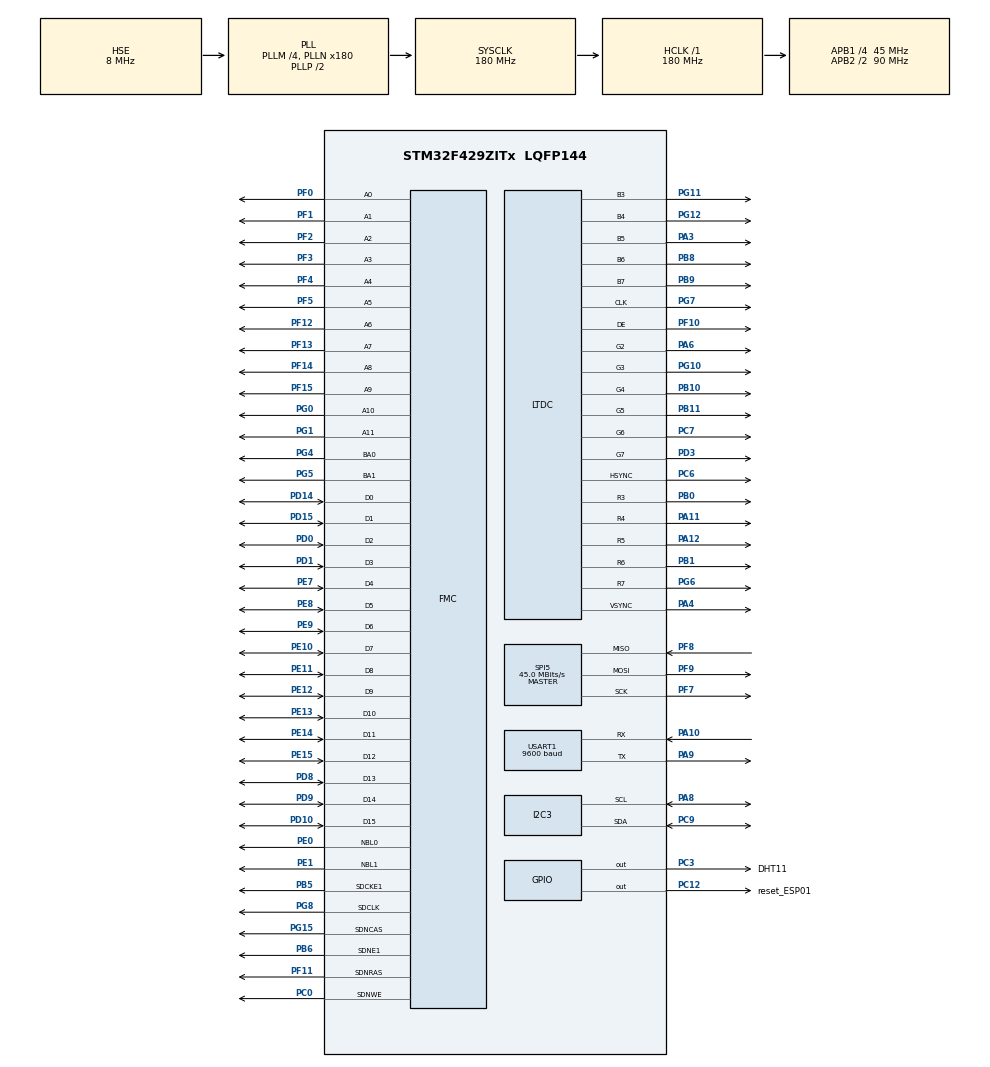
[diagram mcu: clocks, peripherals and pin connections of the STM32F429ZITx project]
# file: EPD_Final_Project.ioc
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DMA2D.ColorMode=DMA2D_OUTPUT_RGB565
LTDC.ActiveH=320
LTDC.ActiveW=240
LTDC.Alpha_L0=255
LTDC.BlendingFactor1_L0=LTDC_BLENDING_FACTOR1_PAxCA
LTDC.BlendingFactor2_L0=LTDC_BLENDING_FACTOR2_PAxCA
LTDC.HBP=20
LTDC.HFP=10
LTDC.HSync=10
LTDC.ImageHeight_L0=320
LTDC.ImageWidth_L0=240
LTDC.Layers=0
LTDC.PixelFormat_L0=LTDC_PIXEL_FORMAT_RGB565
LTDC.VFP=4
LTDC.VSync=2
LTDC.WindowX1_L0=240
LTDC.WindowY1_L0=320
Mcu.Family=STM32F4
Mcu.Name=STM32F429ZITx
Mcu.Package=LQFP144
NVIC.LTDC_IRQn=true\:1\:0\:true\:false\:true\:true\:true\:true
NVIC.PriorityGroup=NVIC_PRIORITYGROUP_4
PA10.Mode=Asynchronous
PA10.Signal=USART1_RX
PA11.Mode=RGB565
PA11.Signal=LTDC_R4
PA12.Mode=RGB565
PA12.Signal=LTDC_R5
PA13.Mode=Serial_Wire
PA13.Signal=SYS_JTMS-SWDIO
PA14.Mode=Serial_Wire
PA14.Signal=SYS_JTCK-SWCLK
PA3.Mode=RGB565
PA3.Signal=LTDC_B5
PA4.Mode=RGB565
PA4.Signal=LTDC_VSYNC
PA6.Mode=RGB565
PA6.Signal=LTDC_G2
PA8.Mode=I2C
PA8.Signal=I2C3_SCL
PA9.Mode=Asynchronous
PA9.Signal=USART1_TX
PB0.Mode=RGB565
PB0.Signal=LTDC_R3
PB1.Mode=RGB565
PB1.Signal=LTDC_R6
PB10.Mode=RGB565
PB10.Signal=LTDC_G4
PB11.Mode=RGB565
PB11.Signal=LTDC_G5
PB5.Mode=SdramChipSelect2_1
PB5.Signal=FMC_SDCKE1
PB6.Mode=SdramChipSelect2_1
PB6.Signal=FMC_SDNE1
PB8.Mode=RGB565
PB8.Signal=LTDC_B6
PB9.Mode=RGB565
PB9.Signal=LTDC_B7
PC0.Signal=FMC_SDNWE
PC12.GPIO_Label=reset_ESP01
PC12.GPIO_ModeDefaultOutputPP=GPIO_MODE_OUTPUT_PP
PC12.GPIO_PuPd=GPIO_PULLUP
PC12.GPIO_Speed=GPIO_SPEED_FREQ_VERY_HIGH
PC12.PinState=GPIO_PIN_SET
PC12.Signal=GPIO_Output
PC3.GPIO_Label=DHT11
PC3.Signal=GPIO_Output
PC6.Mode=RGB565
PC6.Signal=LTDC_HSYNC
PC7.Mode=RGB565
PC7.Signal=LTDC_G6
PC9.Mode=I2C
PC9.Signal=I2C3_SDA
PD0.Signal=FMC_D2_DA2
PD1.Signal=FMC_D3_DA3
PD10.Signal=FMC_D15_DA15
PD14.Signal=FMC_D0_DA0
PD15.Signal=FMC_D1_DA1
PD3.Mode=RGB565
PD3.Signal=LTDC_G7
PD8.Signal=FMC_D13_DA13
PD9.Signal=FMC_D14_DA14
PE0.Signal=FMC_NBL0
PE1.Signal=FMC_NBL1
PE10.Signal=FMC_D7_DA7
PE11.Signal=FMC_D8_DA8
PE12.Signal=FMC_D9_DA9
PE13.Signal=FMC_D10_DA10
PE14.Signal=FMC_D11_DA11
PE15.Signal=FMC_D12_DA12
PE7.Signal=FMC_D4_DA4
PE8.Signal=FMC_D5_DA5
PE9.Signal=FMC_D6_DA6
PF0.Signal=FMC_A0
PF1.Signal=FMC_A1
PF10.Mode=RGB565
PF10.Signal=LTDC_DE
PF11.Signal=FMC_SDNRAS
PF12.Signal=FMC_A6
PF13.Signal=FMC_A7
PF14.Signal=FMC_A8
PF15.Signal=FMC_A9
PF2.Signal=FMC_A2
PF3.Signal=FMC_A3
PF4.Signal=FMC_A4
PF5.Signal=FMC_A5
PF7.Mode=Full_Duplex_Master
PF7.Signal=SPI5_SCK
PF8.Mode=Full_Duplex_Master
PF8.Signal=SPI5_MISO
PF9.Mode=Full_Duplex_Master
PF9.Signal=SPI5_MOSI
PG0.Signal=FMC_A10
PG1.Signal=FMC_A11
PG10.Mode=RGB565
PG10.Signal=LTDC_G3
PG11.Mode=RGB565
PG11.Signal=LTDC_B3
PG12.Mode=RGB565
PG12.Signal=LTDC_B4
PG15.Signal=FMC_SDNCAS
PG4.Signal=FMC_A14_BA0
PG5.Signal=FMC_A15_BA1
PG6.Mode=RGB565
PG6.Signal=LTDC_R7
PG7.Mode=RGB565
PG7.Signal=LTDC_CLK
PG8.Signal=FMC_SDCLK
PH0/OSC_IN.Mode=HSE-External-Oscillator
PH0/OSC_IN.Signal=RCC_OSC_IN
PH1/OSC_OUT.Mode=HSE-External-Oscillator
PH1/OSC_OUT.Signal=RCC_OSC_OUT
ProjectManager.HeapSize=0x200
ProjectManager.StackSize=0x400
ProjectManager.TargetToolchain=STM32CubeIDE
RCC.48MHZClocksFreq_Value=90000000
RCC.AHBFreq_Value=180000000
RCC.APB1CLKDivider=RCC_HCLK_DIV4
RCC.APB1Freq_Value=45000000
RCC.APB1TimFreq_Value=90000000
RCC.APB2CLKDivider=RCC_HCLK_DIV2
RCC.APB2Freq_Value=90000000
RCC.APB2TimFreq_Value=180000000
RCC.CortexFreq_Value=180000000
RCC.EnbaleCSS=true
RCC.HCLKFreq_Value=180000000
RCC.HSE_VALUE=8000000
RCC.HSI_VALUE=16000000
RCC.LSE_VALUE=32768
RCC.PLLM=4
RCC.PLLN=180
RCC.PLLSAIN=50
RCC.PLLSAIR=4
RCC.PLLSourceVirtual=RCC_PLLSOURCE_HSE
RCC.RCC_RTC_Clock_Source=RCC_RTCCLKSOURCE_LSI
RCC.RCC_RTC_Clock_SourceVirtual=RCC_RTCCLKSOURCE_LSE
RCC.RCC_RTC_Clock_Source_FROM_HSE=RCC_RTCCLKSOURCE_HSE_DIV8
RCC.SYSCLKFreq_VALUE=180000000
RCC.SYSCLKSource=RCC_SYSCLKSOURCE_PLLCLK
RCC.VCOOutputFreq_Value=360000000
RTC.Date=27
RTC.Format=RTC_FORMAT_BIN
RTC.Hours=9
RTC.Minutes=10
RTC.Month=RTC_MONTH_MAY
RTC.WeekDay=RTC_WEEKDAY_SATURDAY
RTC.Year=23
SH.FMC_A0.0=FMC_A0,12b-sda1
SH.FMC_A1.0=FMC_A1,12b-sda1
SH.FMC_A10.0=FMC_A10,12b-sda1
SH.FMC_A11.0=FMC_A11,12b-sda1
SH.FMC_A14_BA0.0=FMC_BA0,FourSdramBanks1
SH.FMC_A15_BA1.0=FMC_BA1,FourSdramBanks1
SH.FMC_A2.0=FMC_A2,12b-sda1
SH.FMC_A3.0=FMC_A3,12b-sda1
SH.FMC_A4.0=FMC_A4,12b-sda1
SH.FMC_A5.0=FMC_A5,12b-sda1
SH.FMC_A6.0=FMC_A6,12b-sda1
SH.FMC_A7.0=FMC_A7,12b-sda1
SH.FMC_A8.0=FMC_A8,12b-sda1
SH.FMC_A9.0=FMC_A9,12b-sda1
SH.FMC_D0_DA0.0=FMC_D0,sd-16b-d1
SH.FMC_D10_DA10.0=FMC_D10,sd-16b-d1
SH.FMC_D11_DA11.0=FMC_D11,sd-16b-d1
SH.FMC_D12_DA12.0=FMC_D12,sd-16b-d1
SH.FMC_D13_DA13.0=FMC_D13,sd-16b-d1
SH.FMC_D14_DA14.0=FMC_D14,sd-16b-d1
SH.FMC_D15_DA15.0=FMC_D15,sd-16b-d1
SH.FMC_D1_DA1.0=FMC_D1,sd-16b-d1
SH.FMC_D2_DA2.0=FMC_D2,sd-16b-d1
SH.FMC_D3_DA3.0=FMC_D3,sd-16b-d1
SH.FMC_D4_DA4.0=FMC_D4,sd-16b-d1
SH.FMC_D5_DA5.0=FMC_D5,sd-16b-d1
SH.FMC_D6_DA6.0=FMC_D6,sd-16b-d1
SH.FMC_D7_DA7.0=FMC_D7,sd-16b-d1
SH.FMC_D8_DA8.0=FMC_D8,sd-16b-d1
SH.FMC_D9_DA9.0=FMC_D9,sd-16b-d1
SH.FMC_NBL0.0=FMC_NBL0,Sd2ByteEnable1
SH.FMC_NBL1.0=FMC_NBL1,Sd2ByteEnable1
SH.FMC_SDCLK.0=FMC_SDCLK,12b-sda1
SH.FMC_SDNCAS.0=FMC_SDNCAS,12b-sda1
SH.FMC_SDNRAS.0=FMC_SDNRAS,12b-sda1
SH.FMC_SDNWE.0=FMC_SDNWE,12b-sda1
SPI5.CalculateBaudRate=45.0 MBits/s
SPI5.Direction=SPI_DIRECTION_2LINES
SPI5.Mode=SPI_MODE_MASTER
SPI5.VirtualType=VM_MASTER
TIM6.Prescaler=90-1
USART1.BaudRate=9600
USART1.VirtualMode=VM_ASYNC
VP_DMA2D_VS_DMA2D.Mode=DMA2D_Activate
VP_RTC_VS_RTC_Activate.Mode=RTC_Enabled
VP_RTC_VS_RTC_Calendar.Mode=RTC_Calendar
VP_TIM6_VS_ClockSourceINT.Mode=Enable_Timer
board=custom

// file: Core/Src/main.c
/* USER CODE BEGIN Header */
/**
  ******************************************************************************
  * @file           : main.c
  * @brief          : Main program body
  ******************************************************************************
  * @attention
  *
  * Copyright (c) 2023 STMicroelectronics.
  * All rights reserved.
  *
  * This software is licensed under terms that can be found in the LICENSE file
  * in the root directory of this software component.
  * If no LICENSE file comes with this software, it is provided AS-IS.
  *
  ******************************************************************************
  */
/* USER CODE END Header */
#include "main.h"
#include "dma2d.h"
#include "i2c.h"
#include "ltdc.h"
#include "rtc.h"
#include "spi.h"
#include "tim.h"
#include "usart.h"
#include "gpio.h"
#include "fmc.h"

/* USER CODE BEGIN Includes */
#include <stdio.h>
#include <string.h>
#include "stm32f429i_discovery_lcd.h"
#include <stdio.h>
#include "./image/display_1.h"
#include "./image/display_2.h"

/* ESP8266 part(start) */
void ESP8266_Init();
void ESP8266_SendData(int16_t sensor1_data,int16_t sensor2_data);
int32_t checkBufferCharacters(uint8_t* buffer, const char* targetString);
/* ESP8266 part(end) */

/* USER CODE END Includes */

/* USER CODE BEGIN PD */

#define DHT22_PORT GPIOC
#define DHT22_PIN GPIO_PIN_3

/* USER CODE END PD */

/* USER CODE BEGIN PV */

uint8_t 	stimebuf[30]={0};
uint8_t 	sdatebuf[30]={0};
RTC_TimeTypeDef sTime={0};
RTC_DateTypeDef sDate={0};

/* ESP8266 part(start) */
uint8_t at_inst1[]="AT+CIPSTART=\"TCP\",\"184.106.153.149\",80\r\n";
char at_inst2[16];
uint8_t at_inst4[]="AT+CIPCLOSE\r\n";

#define BUFFER_SIZE 64
uint8_t rx_buffer_init[128];
uint8_t rx_buffer1[BUFFER_SIZE];
uint8_t rx_buffer2[BUFFER_SIZE];
uint8_t rx_buffer3[BUFFER_SIZE];
uint8_t rx_buffer4[BUFFER_SIZE];

int32_t init_receive_ok=0;
int32_t inst1_receive_ok=0;
int32_t inst2_receive_ok=0;
int32_t inst3_receive_ok=0;
int32_t inst4_receive_ok=0;

int32_t timeout=0;

/* ESP8266 part(end) */

/* DHT11 part(start) */
void delay (uint16_t time);
void Set_Pin_Output (GPIO_TypeDef *GPIOx, uint16_t GPIO_Pin);
void Set_Pin_Input (GPIO_TypeDef *GPIOx, uint16_t GPIO_Pin);
void DHT22_Start (void);
uint8_t DHT22_Check_Response (void);
uint8_t DHT22_Read (void);
uint8_t Rh_byte1, Rh_byte2, Temp_byte1, Temp_byte2;
uint16_t SUM, RH, TEMP;
int16_t Temperature = 0;
int16_t Humidity = 0;
uint8_t Presence = 0;
int32_t timeout_DHT=0;
/* DHT11 part(end) */

uint8_t humidityString[10] = {0};
uint8_t TemperatureString[10] = {0};

/* USER CODE END PV */

void SystemClock_Config(void);

int main(void)
{

  /* MCU Configuration--------------------------------------------------------*/

  /* Reset of all peripherals, Initializes the Flash interface and the Systick. */
     HAL_Init();

  /* Configure the system clock */
  SystemClock_Config();

  /* Initialize all configured peripherals */
  MX_GPIO_Init();
  MX_DMA2D_Init();
  MX_LTDC_Init();
  MX_FMC_Init();
  MX_I2C3_Init();
  MX_SPI5_Init();
  MX_TIM6_Init();
  MX_USART1_UART_Init();
  MX_RTC_Init();
  /* USER CODE BEGIN 2 */
  BSP_LCD_Init();

  BSP_LCD_LayerDefaultInit(LCD_BACKGROUND_LAYER, LCD_FRAME_BUFFER);
  BSP_LCD_LayerDefaultInit(LCD_FOREGROUND_LAYER, LCD_FRAME_BUFFER);
  BSP_LCD_SelectLayer(LCD_FOREGROUND_LAYER);
  BSP_LCD_DisplayOn();
  BSP_LCD_Clear(LCD_COLOR_GRAY);
  HAL_TIM_Base_Start(&htim6);

  /* USER CODE END 2 */

  /* Infinite loop */
  /* USER CODE BEGIN WHILE */
  while (1)
  {
	  HAL_RTC_GetTime(&hrtc, &sTime, RTC_FORMAT_BIN);
	  HAL_RTC_GetDate(&hrtc, &sDate, RTC_FORMAT_BIN);

	  sprintf ((char*)stimebuf,"%02u:%02u",sTime.Hours, sTime.Minutes);
	  BSP_LCD_DrawRect(0,0,240,18);
	  BSP_LCD_SetTextColor(LCD_COLOR_DARKGRAY);
	  BSP_LCD_FillRect(0,0,240,18);
	  BSP_LCD_SetFont(&Font16);
	  BSP_LCD_SetTextColor(LCD_COLOR_WHITE);
	  BSP_LCD_SetBackColor(LCD_COLOR_DARKGRAY);
	  BSP_LCD_DisplayStringAt(0, 0, stimebuf, RIGHT_MODE);

	  sprintf ((char*)sdatebuf,"%02u/%02u/%02u",sDate.Year, sDate.Month,sDate.Date);
	  BSP_LCD_SetFont(&Font16);
	  BSP_LCD_SetTextColor(LCD_COLOR_WHITE);
	  BSP_LCD_SetBackColor(LCD_COLOR_DARKGRAY);
	  BSP_LCD_DisplayStringAt(0, 0, sdatebuf, LEFT_MODE);
	  //
	  //
	  BSP_LCD_SetFont(&Font24);
	  BSP_LCD_SetTextColor(LCD_COLOR_WHITE);
	  BSP_LCD_SetBackColor(LCD_COLOR_DARKGRAY);
	  BSP_LCD_DisplayStringAtLine(2, (uint8_t*) "Temperature       ");
	  //
	  BSP_LCD_SetFont(&Font24);
	  BSP_LCD_SetTextColor(LCD_COLOR_WHITE);
	  BSP_LCD_SetBackColor(LCD_COLOR_DARKGRAY);
	  BSP_LCD_DisplayStringAtLine(5, (uint8_t*) "Humidity         ");
	  //
	  BSP_LCD_SetFont(&Font24);
	  BSP_LCD_SetTextColor(LCD_COLOR_WHITE);
	  BSP_LCD_SetBackColor(LCD_COLOR_DARKGRAY);
	  BSP_LCD_DisplayStringAtLine(8, (uint8_t*) "State             ");
	  //
	  BSP_LCD_DrawRect(95,233,20,20);
	  BSP_LCD_SetTextColor(LCD_COLOR_ORANGE);
	  BSP_LCD_FillRect(95,233,20,20);
	  BSP_LCD_SetFont(&Font20);
	  BSP_LCD_SetTextColor(LCD_COLOR_BLACK);
	  BSP_LCD_SetBackColor(LCD_COLOR_GRAY);
	  BSP_LCD_DisplayStringAt(0, 235, (uint8_t*)"Sensor", LEFT_MODE);
	  //
	  BSP_LCD_SetFont(&Font16);
	  BSP_LCD_SetTextColor(LCD_COLOR_BLACK);
	  BSP_LCD_SetBackColor(LCD_COLOR_GRAY);
	  BSP_LCD_DisplayStringAt(0, 270, (uint8_t*)"    :Done", LEFT_MODE);
	  BSP_LCD_DrawRect(27,267,15,15);
	  BSP_LCD_SetTextColor(LCD_COLOR_GREEN);
	  BSP_LCD_FillRect(27,267,15,15);
	  //
	  BSP_LCD_SetFont(&Font16);
	  BSP_LCD_SetTextColor(LCD_COLOR_BLACK);
	  BSP_LCD_SetBackColor(LCD_COLOR_GRAY);
	  BSP_LCD_DisplayStringAt(0, 270, (uint8_t*)":Working ", RIGHT_MODE);
	  BSP_LCD_DrawRect(115,267,15,15);
	  BSP_LCD_SetTextColor(LCD_COLOR_ORANGE);
	  BSP_LCD_FillRect(115,267,15,15);
	  //
	  BSP_LCD_SetFont(&Font16);
	  BSP_LCD_SetTextColor(LCD_COLOR_BLACK);
	  BSP_LCD_SetBackColor(LCD_COLOR_GRAY);
	  BSP_LCD_DisplayStringAt(0, 295, (uint8_t*)"   :Failed", CENTER_MODE);
	  BSP_LCD_DrawRect(75,292,15,15);
	  BSP_LCD_SetTextColor(LCD_COLOR_RED);
	  BSP_LCD_FillRect(75,292,15,15);
	  //
	  HAL_Delay(1500);
	  DHT22_Start();
	  Presence = DHT22_Check_Response();
	  if (Presence!=1)
	  {
		  HAL_Delay(3000);
		  timeout_DHT=0;
		  continue;
	  }
	  Rh_byte1 = DHT22_Read ();
	  Rh_byte2 = DHT22_Read ();
	  Temp_byte1 = DHT22_Read ();
	  Temp_byte2 = DHT22_Read ();
	  SUM = DHT22_Read();
	  if (SUM == (Rh_byte1+Rh_byte2+Temp_byte1+Temp_byte2))
	  {
	  Temperature = (Temp_byte1<<8|Temp_byte2)/10;
	  Humidity = (Rh_byte1<<8|Rh_byte2)/10;
	  //
	  BSP_LCD_DrawRect(95,233,20,20);
	  BSP_LCD_SetTextColor(LCD_COLOR_GREEN);
	  BSP_LCD_FillRect(95,233,20,20);
	  }
	  //Temperature++;
	  //Humidity++;
	  //
	  sprintf((char*)TemperatureString, "%d.c", Temperature);
	  BSP_LCD_SetFont(&Font24);
	  BSP_LCD_SetTextColor(LCD_COLOR_BLACK);
	  BSP_LCD_SetBackColor(LCD_COLOR_GRAY);
	  BSP_LCD_DisplayStringAt(0, 90, TemperatureString, CENTER_MODE);
	  //
	  sprintf((char*)humidityString, "%d%%", Humidity);
	  BSP_LCD_SetFont(&Font24);
	  BSP_LCD_SetTextColor(LCD_COLOR_BLACK);
	  BSP_LCD_SetBackColor(LCD_COLOR_GRAY);
	  BSP_LCD_DisplayStringAt(0,162,humidityString, CENTER_MODE);
	  HAL_Delay(1000);
	  //
	  BSP_LCD_SetFont(&Font20);
	  BSP_LCD_SetTextColor(LCD_COLOR_BLACK);
	  BSP_LCD_SetBackColor(LCD_COLOR_GRAY);
	  BSP_LCD_DisplayStringAt(0, 235, (uint8_t*)"Upload  ", RIGHT_MODE);
	  BSP_LCD_DrawRect(215,233,20,20);
	  BSP_LCD_SetTextColor(LCD_COLOR_ORANGE);
	  BSP_LCD_FillRect(215,233,20,20);
	  //
	  ESP8266_Init();
	  ESP8266_SendData(Temperature, Humidity);
	  Presence = 0;
	  HAL_Delay(1500);
	  init_receive_ok=0;

    /* USER CODE END WHILE */

  }
}

void SystemClock_Config(void)
{
  RCC_OscInitTypeDef RCC_OscInitStruct = {0};
  RCC_ClkInitTypeDef RCC_ClkInitStruct = {0};

  /** Configure the main internal regulator output voltage
  */
  __HAL_RCC_PWR_CLK_ENABLE();
  __HAL_PWR_VOLTAGESCALING_CONFIG(PWR_REGULATOR_VOLTAGE_SCALE1);

  /** Initializes the RCC Oscillators according to the specified parameters
  * in the RCC_OscInitTypeDef structure.
  */
  RCC_OscInitStruct.OscillatorType = RCC_OSCILLATORTYPE_LSI|RCC_OSCILLATORTYPE_HSE;
  RCC_OscInitStruct.HSEState = RCC_HSE_ON;
  RCC_OscInitStruct.LSIState = RCC_LSI_ON;
  RCC_OscInitStruct.PLL.PLLState = RCC_PLL_ON;
  RCC_OscInitStruct.PLL.PLLSource = RCC_PLLSOURCE_HSE;
  RCC_OscInitStruct.PLL.PLLM = 4;
  RCC_OscInitStruct.PLL.PLLN = 180;
  RCC_OscInitStruct.PLL.PLLP = RCC_PLLP_DIV2;
  RCC_OscInitStruct.PLL.PLLQ = 4;
  if (HAL_RCC_OscConfig(&RCC_OscInitStruct) != HAL_OK)
  {
    Error_Handler();
  }

  /** Activate the Over-Drive mode
  */
  if (HAL_PWREx_EnableOverDrive() != HAL_OK)
  {
    Error_Handler();
  }

  /** Initializes the CPU, AHB and APB buses clocks
  */
  RCC_ClkInitStruct.ClockType = RCC_CLOCKTYPE_HCLK|RCC_CLOCKTYPE_SYSCLK
                              |RCC_CLOCKTYPE_PCLK1|RCC_CLOCKTYPE_PCLK2;
  RCC_ClkInitStruct.SYSCLKSource = RCC_SYSCLKSOURCE_PLLCLK;
  RCC_ClkInitStruct.AHBCLKDivider = RCC_SYSCLK_DIV1;
  RCC_ClkInitStruct.APB1CLKDivider = RCC_HCLK_DIV4;
  RCC_ClkInitStruct.APB2CLKDivider = RCC_HCLK_DIV2;

  if (HAL_RCC_ClockConfig(&RCC_ClkInitStruct, FLASH_LATENCY_5) != HAL_OK)
  {
    Error_Handler();
  }

  /** Enables the Clock Security System
  */
  HAL_RCC_EnableCSS();
}

/* USER CODE BEGIN 4 */

/* ESP8266 part(start) */
void ESP8266_Init(){
    memset(rx_buffer_init, 0, sizeof(rx_buffer_init));
    init_receive_ok=0;

    while(init_receive_ok!=1){

    HAL_GPIO_WritePin(GPIOC, GPIO_PIN_12, GPIO_PIN_RESET);
	HAL_Delay(1000);
	HAL_GPIO_WritePin(GPIOC, GPIO_PIN_12, GPIO_PIN_SET);
	HAL_UART_Receive(&huart1, rx_buffer_init, sizeof(rx_buffer_init)-1, 1000);
	init_receive_ok=checkBufferCharacters(rx_buffer_init, "SystemReady");
	}
}

void ESP8266_SendData(int16_t sensor1_data,int16_t sensor2_data) {

    inst1_receive_ok=0;
    inst2_receive_ok=0;
    inst3_receive_ok=0;
    inst4_receive_ok=0;
    HAL_Delay(5000);

    timeout=0;
    while(inst1_receive_ok==0 && timeout<=5){
	HAL_UART_Transmit(&huart1, at_inst1, sizeof(at_inst1) - 1, 1000);
	HAL_UART_Receive(&huart1, rx_buffer1, sizeof(rx_buffer1)-1, 1000);
	inst1_receive_ok = checkBufferCharacters(rx_buffer1, "Linked")||checkBufferCharacters(rx_buffer1, "CONNECT");
	HAL_Delay(3000);
	timeout++;
    }
    if(inst1_receive_ok!=1){
    	BSP_LCD_DrawRect(215,233,20,20);
    	BSP_LCD_SetTextColor(LCD_COLOR_RED);
    	BSP_LCD_FillRect(215,233,20,20);
    	return;
    }

    uint8_t sensor1_name[]="&field1=";
    uint8_t sensor2_name[]="&field2=";
    uint8_t at_inst3_temp1[]="GET /update?api_key=V8CUO3DJT76JJ3XW";
    int16_t at_inst3_length=0;
    int16_t inst3_length=0;

    at_inst3_length=0;
    inst3_length=0;
    at_inst3_length = strlen((const char*)at_inst3_temp1) + strlen((const char*)sensor1_name) + strlen((const char*)&sensor1_data)+ strlen((const char*)sensor2_name) + strlen((const char*)&sensor2_data)+4;    //計�?�inst3??��?�串總長度�??+4?��\r\n
    uint8_t at_inst3[at_inst3_length];

    sprintf((char*)at_inst3,"GET /update?api_key=V8CUO3DJT76JJ3XW%s%d%s%d\r\n",(char*)sensor1_name,sensor1_data,(char*)sensor2_name,sensor2_data);    //組�?�inst3

    inst3_length = strlen((char*)at_inst3);
    sprintf(at_inst2, "AT+CIPSEND=%d\r\n",inst3_length);

    timeout=0;
    while(inst2_receive_ok==0 && timeout<=5){
    HAL_UART_Transmit(&huart1, (uint8_t*)at_inst2, sizeof(at_inst2) - 1, 1000);
    HAL_UART_Receive(&huart1, rx_buffer2, sizeof(rx_buffer2)-1, 1000);
    inst2_receive_ok = checkBufferCharacters(rx_buffer2, ">");
    HAL_Delay(3000);
    timeout++;
    }
    if(inst2_receive_ok!=1){
    	BSP_LCD_DrawRect(215,233,20,20);
    	BSP_LCD_SetTextColor(LCD_COLOR_RED);
    	BSP_LCD_FillRect(215,233,20,20);
    	return;
    }
    HAL_Delay(1000);

    timeout=0;
    while(inst3_receive_ok==0 && timeout<=5)
    {
        HAL_UART_Transmit(&huart1, (uint8_t*)at_inst3, inst3_length, 1000);
        HAL_UART_Receive(&huart1, rx_buffer3, sizeof(rx_buffer3)-1, 1000);
        inst3_receive_ok = checkBufferCharacters(rx_buffer3, "SENDOKIPD");
        HAL_Delay(3000);
        timeout++;
    }
    if(inst3_receive_ok==1)
    {
    	BSP_LCD_DrawRect(215,233,20,20);
    	BSP_LCD_SetTextColor(LCD_COLOR_GREEN);
    	BSP_LCD_FillRect(215,233,20,20);
    }
    else if(inst3_receive_ok!=1)
    {
    	BSP_LCD_DrawRect(215,233,20,20);
    	BSP_LCD_SetTextColor(LCD_COLOR_RED);
    	BSP_LCD_FillRect(215,233,20,20);
    	return;
    }

    HAL_Delay(1000);

    timeout=0;
    while(inst4_receive_ok==0 && timeout<=5){
	HAL_UART_Transmit(&huart1, (uint8_t*)at_inst4, sizeof(at_inst4) - 1, 1000);
	HAL_UART_Receive(&huart1, rx_buffer4, sizeof(rx_buffer4)-1, 1000);
	inst4_receive_ok = checkBufferCharacters(rx_buffer4, "A");
	HAL_Delay(3000);
	timeout++;
    }
    if(inst4_receive_ok!=1){
	return;
	}
    HAL_Delay(1000);

    memset(rx_buffer1, 0, sizeof(rx_buffer1));
    memset(rx_buffer2, 0, sizeof(rx_buffer2));
    memset(rx_buffer3, 0, sizeof(rx_buffer3));
    memset(rx_buffer4, 0, sizeof(rx_buffer4));
}

int32_t checkBufferCharacters(uint8_t* buffer, const char* targetString){
    uint32_t targetLen = strlen(targetString);

    for (uint32_t i = 0; i < targetLen; i++){
        int found = 0;
        for (uint32_t j = 0; j < BUFFER_SIZE; j++){
            if (buffer[j] == targetString[i]) {
                found = 1;
                break;
            }
        }
        if (!found) {
            return 0;
        }
    }
    return 1;
}
/* ESP8266 part(end) */

/* DHT22 part(start) */
void delay (uint16_t time)
{

	__HAL_TIM_SET_COUNTER(&htim6, 0);
	while ((__HAL_TIM_GET_COUNTER(&htim6))<time);
}

void Set_Pin_Output (GPIO_TypeDef *GPIOx, uint16_t GPIO_Pin)
{
	GPIO_InitTypeDef GPIO_InitStruct = {0};
	GPIO_InitStruct.Pin = GPIO_Pin;
	GPIO_InitStruct.Mode = GPIO_MODE_OUTPUT_OD;
	GPIO_InitStruct.Speed = GPIO_SPEED_FREQ_LOW;
	HAL_GPIO_Init(GPIOx, &GPIO_InitStruct);
}

void Set_Pin_Input (GPIO_TypeDef *GPIOx, uint16_t GPIO_Pin)
{
	GPIO_InitTypeDef GPIO_InitStruct = {0};
	GPIO_InitStruct.Pin = GPIO_Pin;
	GPIO_InitStruct.Mode = GPIO_MODE_INPUT;
	GPIO_InitStruct.Pull = GPIO_PULLUP;
	//GPIO_NOPULL
	HAL_GPIO_Init(GPIOx, &GPIO_InitStruct);
}

void DHT22_Start (void)
{
	Set_Pin_Output (DHT22_PORT, DHT22_PIN);
	HAL_GPIO_WritePin (DHT22_PORT, DHT22_PIN, 0);
	delay (1200);
    HAL_GPIO_WritePin (DHT22_PORT, DHT22_PIN, 1);
	delay (20);
	Set_Pin_Input(DHT22_PORT, DHT22_PIN);
}

uint8_t DHT22_Check_Response (void)
{
    uint8_t Response = 0;
    timeout_DHT=0;
    delay (40);
	if ((HAL_GPIO_ReadPin (DHT22_PORT, DHT22_PIN))==0){

            delay (40);

	    if ((HAL_GPIO_ReadPin (DHT22_PORT, DHT22_PIN))==1){
	    	Response = 1;
	    	delay (80);
	    }
	    else Response = -1; // 255
	}

    return Response;
}

 uint8_t DHT22_Read (void)
{
    uint8_t i,j;
    while ((HAL_GPIO_ReadPin (DHT22_PORT, DHT22_PIN)));
    for (j=0;j<8;j++)
    {
	    while (!(HAL_GPIO_ReadPin (DHT22_PORT, DHT22_PIN)));
	    delay (50);
	    if (!(HAL_GPIO_ReadPin (DHT22_PORT, DHT22_PIN)))
	{
		i&= ~(1<<(7-j));
	}
	    else i|= (1<<(7-j));
    while ((HAL_GPIO_ReadPin (DHT22_PORT, DHT22_PIN)));
    }
    return i;
}
/* DHT22 part(end) */

/* USER CODE END 4 */

void Error_Handler(void)
{
  __disable_irq();
  while (1)
  {
  }
}
